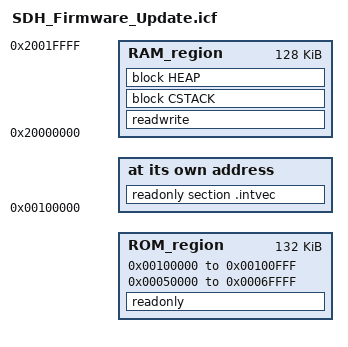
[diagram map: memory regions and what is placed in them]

define memory mem with size = 4G;
define region ROM_region   = mem:[from 0x100000 size 0x1000] | mem:[from 0x50000 size 0x20000];
define region RAM_region   = mem:[from 0x20000000 size 0x20000];

define block CSTACK    with alignment = 8, size = 0x4000   { };
define block HEAP      with alignment = 8, size = 0x1000   { };

initialize by copy { readwrite };
do not initialize  { section .noinit };

place at address mem:0x100000 { readonly section .intvec };

place in ROM_region   { readonly };
place in RAM_region   { readwrite,
                        block CSTACK, block HEAP };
